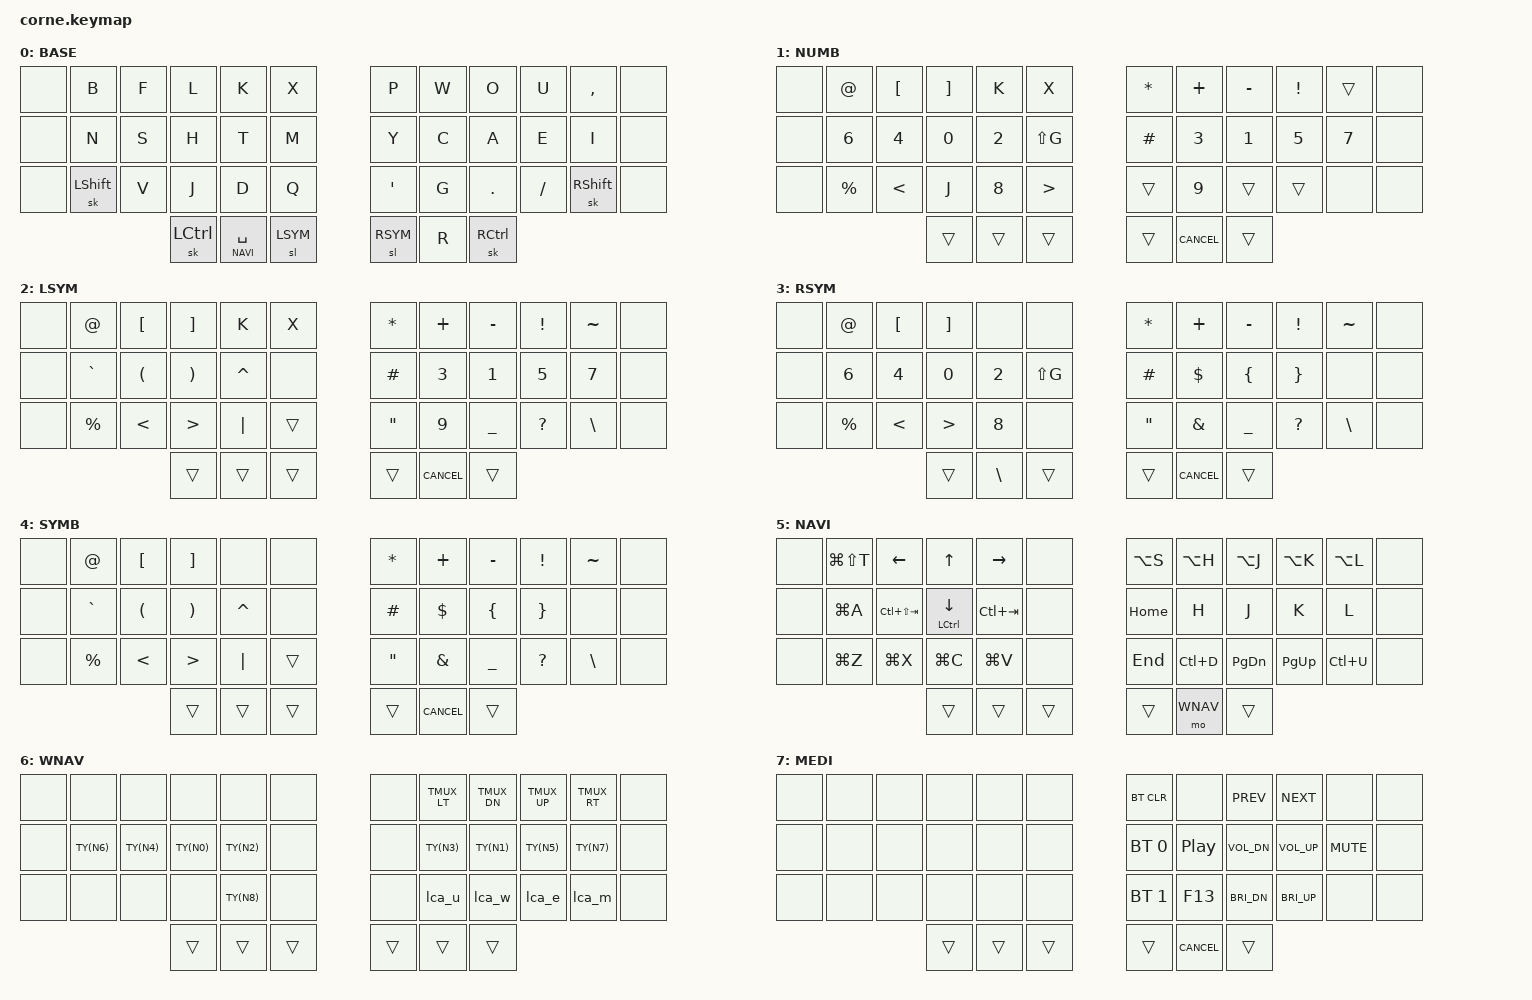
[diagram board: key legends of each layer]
/*
 * Copyright (c) 2020 The ZMK Contributors
 *
 * SPDX-License-Identifier: MIT
 */

#include <behaviors.dtsi>
#include <behaviors/num_word.dtsi>
#include <dt-bindings/zmk/keys.h>
#include <dt-bindings/zmk/bt.h>
#include "corne.h"
#include "zmk-helpers/helper.h"
#include "zmk-helpers/key-labels/42.h"

/* Globals */

#define QUICK_TAP_MS 175

&sk {
  release-after-ms = <900>;
  quick-release;
};

&lt {
  flavor = "balanced";
  tapping-term-ms = <200>;
  quick-tap-ms = <QUICK_TAP_MS>;
};

&num_word {
  continue-list = <BSPC DEL DOT COMMA PLUS MINUS STAR FSLH EQUAL>;
};

/* Tmux pane switch on hold, yabai window swap on tap */
#define TY(keycode) &tw keycode LA(keycode)

/ {
        combos {
                #include "combos.dtsi"
        };

        macros {
                #include "macros.dtsi"
        };

        behaviors {
                tw: tmux_window_hold_tap {
                        compatible = "zmk,behavior-hold-tap";
                        #binding-cells = <2>;
                        tapping-term-ms = <200>;
                        quick-tap-ms = <QUICK_TAP_MS>;
                        flavor = "balanced";
                        bindings = <&tmux_window>, <&kp>;
                };
        };

        keymap {
                compatible = "zmk,keymap";
                base_layer {
                        display-name = "BASE";
                        bindings = <
   &none &kp B      &kp F       &kp L         &kp K           &kp X         &kp P        &kp W        &kp O        &kp U          &kp COMMA    &none
   &none &kp N      &kp S       &kp H         &kp T           &kp M         &kp Y        &kp C        &kp A        &kp E          &kp I        &none
   &none &sk LSHFT  &kp V       &kp J         &kp D           &kp Q         &kp APOS     &kp G        &kp DOT      &kp FSLH       &sk RSHFT    &none
                                &sk LCTRL     &lt NAVI SPACE  &sl LSYM      &sl RSYM     &kp R        &sk RCTRL
                        >;
                };
                numb_layer {
                        display-name = "NUMB";
                        bindings = <
   &none &kp AT    &kp LBKT  &kp RBKT  &kp K     &kp X     &kp ASTRK &kp PLUS      &kp MINUS  &kp EXCL  &trans     &none
   &none &kp N6    &kp N4    &kp N0    &kp N2    &kp LS(G) &kp HASH  &kp N3        &kp N1     &kp N5    &kp N7     &none
   &none &kp PRCNT &kp LT    &kp J     &kp N8    &kp GT    &trans    &kp N9        &trans     &trans    &none      &none
                             &trans    &trans    &trans    &trans    &kp K_CANCEL  &trans
                        >;
                };
                lsym_layer {
                        display-name = "LSYM";
                        bindings = <
   &none &kp AT    &kp LBKT  &kp RBKT  &kp K     &kp X     &kp ASTRK &kp PLUS      &kp MINUS  &kp EXCL  &kp TILDE  &none
   &none &kp GRAVE &kp LPAR  &kp RPAR  &kp CARET &none     &kp HASH  &kp N3        &kp N1     &kp N5    &kp N7     &none
   &none &kp PRCNT &kp LT    &kp GT    &kp PIPE  &trans    &kp DQT   &kp N9        &kp UNDER  &kp QMARK &kp BSLH   &none
                             &trans    &trans    &trans    &trans    &kp K_CANCEL  &trans
                        >;
                };
                rsym_layer {
                        display-name = "RSYM";
                        bindings = <
   &none &kp AT    &kp LBKT  &kp RBKT  &none     &none     &kp ASTRK &kp PLUS      &kp MINUS  &kp EXCL  &kp TILDE  &none
   &none &kp N6    &kp N4    &kp N0    &kp N2    &kp LS(G) &kp HASH  &kp DOLLAR    &kp LBRC   &kp RBRC  &none      &none
   &none &kp PRCNT &kp LT    &kp GT    &kp N8    &none     &kp DQT   &kp AMPS      &kp UNDER  &kp QMARK &kp BSLH   &none
                             &trans    &kp BSLH  &trans    &trans    &kp K_CANCEL  &trans
                        >;
                };
                symb_layer {
                        display-name = "SYMB";
                        bindings = <
   &none &kp AT    &kp LBKT  &kp RBKT     &none     &none      &kp ASTRK &kp PLUS      &kp MINUS  &kp EXCL  &kp TILDE    &none
   &none &kp GRAVE &kp LPAR  &kp RPAR     &kp CARET &none      &kp HASH  &kp DOLLAR    &kp LBRC   &kp RBRC  &none        &none
   &none &kp PRCNT &kp LT    &kp GT       &kp PIPE  &trans     &kp DQT   &kp AMPS      &kp UNDER  &kp QMARK &kp BSLH     &none
                             &trans       &trans    &trans     &trans    &kp K_CANCEL  &trans
                        >;
                };
                navi_layer {
                        display-name = "NAVI";
                        bindings = <
   &none &kp LG(LS(T)) &kp LEFT        &kp UP           &kp RIGHT   &none     &kp LA(S)  &kp LA(H) &kp LA(J)  &kp LA(K) &kp LA(L) &none
   &none &kp LG(A)     &kp LC(LS(TAB)) &mt LCTRL DOWN   &kp LC(TAB) &none     &kp HOME   &kp H     &kp J      &kp K     &kp L     &none
   &none &kp LG(Z)     &kp LG(X)       &kp LG(C)        &kp LG(V)   &none     &kp END    &kp LC(D) &kp PG_DN  &kp PG_UP &kp LC(U) &none
                                       &trans           &trans      &trans    &trans     &mo WNAV  &trans
                        >;
                };
                wnav_layer {
                        display-name = "WNAV";
                        bindings = <
   &none &none      &none      &none      &none      &none   &none   TMUX_LT     TMUX_DN      TMUX_UP     TMUX_RT    &none
   &none TY(N6)     TY(N4)     TY(N0)     TY(N2)     &none   &none   TY(N3)      TY(N1)       TY(N5)      TY(N7)     &none
   &none &none      &none      &none      TY(N8)     &none   &none   &lca_u      &lca_w       &lca_e      &lca_m     &none
                               &trans     &trans     &trans  &trans  &trans      &trans
                        >;
                };
                medi_layer {
                        display-name = "MEDI";
                        bindings = <
   &none &none     &none     &none     &none     &none       &bt BT_CLR    &none         &kp C_PREV   &kp C_NEXT    &none       &none
   &none &none     &none     &none     &none     &none       &bt BT_SEL 0  &kp C_PP      &kp C_VOL_DN &kp C_VOL_UP  &kp C_MUTE  &none
   &none &none     &none     &none     &none     &none       &bt BT_SEL 1  &kp F13       &kp C_BRI_DN &kp C_BRI_UP  &none       &none
                             &trans    &trans    &trans      &trans        &kp K_CANCEL  &trans
                        >;
                };
        };
};
